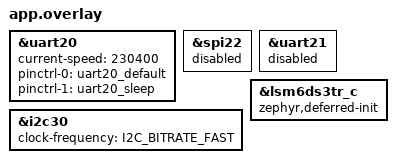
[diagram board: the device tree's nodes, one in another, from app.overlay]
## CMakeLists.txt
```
# Copyright 2026 XR IMU contributors
# SPDX-License-Identifier: Apache-2.0
cmake_minimum_required(VERSION 3.20.0)

find_package(Zephyr REQUIRED HINTS $ENV{ZEPHYR_BASE})
project(xr_imu_xiao_nrf54l15_sense)

target_sources(app PRIVATE
    src/main.c
    src/xr_controller_v1.c
)

target_include_directories(app PRIVATE include)
```

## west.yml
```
manifest:
  version: "1.2"

  remotes:
    - name: zephyrproject-rtos
      url-base: https://github.com/zephyrproject-rtos

  projects:
    - name: zephyr
      remote: zephyrproject-rtos
      revision: v4.4.0
      import:
        name-allowlist:
          - cmsis
          - cmsis_6
          - hal_nordic

  self:
    path: xr-imu-xiao-nrf54l15-sense
```

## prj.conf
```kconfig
# Binary-only UART transport. Never enable console/log output on uart20.
CONFIG_SERIAL=y
CONFIG_UART_ASYNC_API=y
CONFIG_UART_ASYNC_TX_CACHE_SIZE=64
CONFIG_CONSOLE=n
CONFIG_UART_CONSOLE=n
CONFIG_STDOUT_CONSOLE=n
CONFIG_PRINTK=n
CONFIG_LOG=n
CONFIG_BOOT_BANNER=n

# The Sense IMU rail is controlled by the board fixed regulator pdm_imu_pwr
# on P0.1. It must be enabled before the LSM6DSL driver initializes.
CONFIG_GPIO=y
CONFIG_REGULATOR=y
CONFIG_REGULATOR_FIXED=y
CONFIG_I2C=y
CONFIG_SENSOR=y
CONFIG_LSM6DSL=y
CONFIG_FPU=y

CONFIG_MAIN_STACK_SIZE=2048
CONFIG_SYSTEM_WORKQUEUE_STACK_SIZE=1024
CONFIG_HEAP_MEM_POOL_SIZE=0
CONFIG_TICKLESS_KERNEL=y

# Fixed sensor configuration. Avoid runtime sensor_attr_set() during startup.
# Kconfig ODR value 5 = 208 Hz for both accelerometer and gyroscope.
CONFIG_LSM6DSL_ACCEL_FS=16
CONFIG_LSM6DSL_ACCEL_ODR=5
CONFIG_LSM6DSL_GYRO_FS=2000
CONFIG_LSM6DSL_GYRO_ODR=5

CONFIG_HWINFO=y
```

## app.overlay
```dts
/*
 * Copyright 2026 XR IMU contributors
 * SPDX-License-Identifier: Apache-2.0
 */

#include <zephyr/dt-bindings/i2c/i2c.h>

/* uart20 is connected to the on-board SAMD11 CMSIS-DAP/CDC bridge. */
&uart20 {
    current-speed = <230400>;
    pinctrl-0 = <&uart20_default>;
    pinctrl-1 = <&uart20_sleep>;
    pinctrl-names = "default", "sleep";
    status = "okay";
};

/*
 * The upstream board DTS enables spi22 even though its SCK/MISO pins overlap
 * uart20 RX/TX (P1.8/P1.9). Disable it or its pinctrl can steal the UART pins
 * connected to the on-board SAMD11 CDC bridge.
 */
&spi22 {
    status = "disabled";
};

/* P2.7 is also used by the SWO/debug domain; this application does not need
 * the second UART, so keep it disabled while CMSIS-DAP is attached.
 */
&uart21 {
    status = "disabled";
};

/* Keep the two 6-byte sensor register reads comfortably below 2.4 ms. */
&i2c30 {
    clock-frequency = <I2C_BITRATE_FAST>;
};

&lsm6ds3tr_c {
    status = "okay";

    /* Power is controlled by P0.1. Initialize only after main() has
     * explicitly enabled the rail and verified the I2C identity.
     */
    zephyr,deferred-init;
};
```

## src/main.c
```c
/*
 * Copyright 2026 XR IMU contributors
 * SPDX-License-Identifier: Apache-2.0
 */
#include <zephyr/device.h>
#include <zephyr/devicetree.h>
#include <zephyr/drivers/gpio.h>
#include <zephyr/drivers/hwinfo.h>
#include <zephyr/drivers/i2c.h>
#include <zephyr/drivers/sensor.h>
#include <zephyr/drivers/uart.h>
#include <zephyr/kernel.h>
#include <zephyr/sys/util.h>

#include <errno.h>
#include <stdint.h>
#include <stddef.h>

#include "xr_controller_v1.h"

#define XR_IMU_SAMPLE_RATE_HZ 208U
#define XR_IMU_SAMPLE_PERIOD_US_CEIL \
    ((1000000U + XR_IMU_SAMPLE_RATE_HZ - 1U) / XR_IMU_SAMPLE_RATE_HZ)
#define XR_IMU_TX_QUEUE_DEPTH 128U
#define XR_IMU_TX_STACK_SIZE 1536U
#define XR_IMU_TX_PRIORITY 2
#define XR_CONTROLLER_IDENTITY_PERIOD_SAMPLES XR_IMU_SAMPLE_RATE_HZ
#define XR_IMU_TX_MAX_PACKET_SIZE XR_CONTROLLER_V1_PACKET_SIZE

struct tx_packet {
    uint16_t size;
    uint8_t bytes[XR_IMU_TX_MAX_PACKET_SIZE];
};

K_MSGQ_DEFINE(tx_queue, sizeof(struct tx_packet), XR_IMU_TX_QUEUE_DEPTH, 4);

#define XR_IMU_NODE DT_ALIAS(imu0)
static const struct device *const imu_dev = DEVICE_DT_GET(XR_IMU_NODE);
static const struct i2c_dt_spec imu_i2c = I2C_DT_SPEC_GET(XR_IMU_NODE);
static const struct gpio_dt_spec imu_power =
    GPIO_DT_SPEC_GET(DT_NODELABEL(pdm_imu_pwr), enable_gpios);
#define XR_IMU_UART_NODE DT_NODELABEL(uart20)
#define XR_IMU_UART_BAUD DT_PROP(XR_IMU_UART_NODE, current_speed)
#define XR_IMU_UART_BITS_PER_BYTE 10U
#define XR_IMU_UART_MAX_LOAD_PERCENT 90U

BUILD_ASSERT(
    ((XR_IMU_SAMPLE_RATE_HZ * XR_CONTROLLER_V1_PACKET_SIZE) +
      XR_CONTROLLER_IDENTITY_V1_PACKET_SIZE) *
        XR_IMU_UART_BITS_PER_BYTE * 100U <=
        XR_IMU_UART_BAUD * XR_IMU_UART_MAX_LOAD_PERCENT,
    "xr_controller_v1 stream exceeds the configured UART throughput budget");

static const struct device *const uart_dev = DEVICE_DT_GET(XR_IMU_UART_NODE);

#if DT_HAS_ALIAS(led0)
static const struct gpio_dt_spec status_led = GPIO_DT_SPEC_GET(DT_ALIAS(led0), gpios);
#endif

static uint64_t monotonic_time_us(void)
{
    return k_cyc_to_us_floor64(k_cycle_get_64());
}

K_MUTEX_DEFINE(uart_tx_mutex);
K_SEM_DEFINE(uart_tx_done, 0, 1);

static int uart_tx_result;

static void uart_event_callback(const struct device *dev,
                                struct uart_event *event,
                                void *user_data)
{
    ARG_UNUSED(dev);
    ARG_UNUSED(user_data);

    switch (event->type) {
    case UART_TX_DONE:
        uart_tx_result = 0;
        k_sem_give(&uart_tx_done);
        break;
    case UART_TX_ABORTED:
        uart_tx_result = -EIO;
        k_sem_give(&uart_tx_done);
        break;
    default:
        break;
    }
}

static int uart_write_raw(const uint8_t *data, size_t size)
{
    int rc;

    if (!device_is_ready(uart_dev)) {
        return -ENODEV;
    }
    if (size == 0U) {
        return 0;
    }

    k_mutex_lock(&uart_tx_mutex, K_FOREVER);
    k_sem_reset(&uart_tx_done);
    uart_tx_result = -EINPROGRESS;

    rc = uart_tx(uart_dev, data, size, SYS_FOREVER_US);
    if (rc == 0) {
        rc = k_sem_take(&uart_tx_done, K_MSEC(1000));
        if (rc == 0) {
            rc = uart_tx_result;
        } else {
            (void)uart_tx_abort(uart_dev);
            rc = -ETIMEDOUT;
        }
    }

    k_mutex_unlock(&uart_tx_mutex);
    return rc;
}

static void uart_write_text(const char *text)
{
    size_t size = 0U;

    while (text[size] != '\0') {
        ++size;
    }
    (void)uart_write_raw((const uint8_t *)text, size);
}

static char hex_digit(uint8_t value)
{
    value &= 0x0fU;
    return value < 10U ? (char)('0' + value) : (char)('A' + value - 10U);
}

static void uart_write_status_hex8(const char *prefix, uint8_t value)
{
    char suffix[4] = {hex_digit(value >> 4), hex_digit(value), '\n', '\0'};
    uart_write_text(prefix);
    uart_write_text(suffix);
}

static void uart_write_status_i32(const char *prefix, int32_t value)
{
    char digits[12];
    char out[14];
    size_t count = 0U;
    size_t pos = 0U;
    uint32_t magnitude;

    if (value < 0) {
        out[pos++] = '-';
        magnitude = (uint32_t)(-(int64_t)value);
    } else {
        magnitude = (uint32_t)value;
    }

    do {
        digits[count++] = (char)('0' + (magnitude % 10U));
        magnitude /= 10U;
    } while (magnitude != 0U);

    while (count != 0U) {
        out[pos++] = digits[--count];
    }
    out[pos++] = '\n';
    out[pos] = '\0';

    uart_write_text(prefix);
    uart_write_text(out);
}

static int probe_who_am_i(uint16_t address, uint8_t *value)
{
    return i2c_reg_read_byte(imu_i2c.bus, address, 0x0fU, value);
}

static void fatal_signal(const char *status)
{
#if DT_HAS_ALIAS(led0)
    const bool led_ready = gpio_is_ready_dt(&status_led) &&
        gpio_pin_configure_dt(&status_led, GPIO_OUTPUT_INACTIVE) == 0;
#else
    const bool led_ready = false;
#endif

    while (true) {
        uart_write_text(status);
#if DT_HAS_ALIAS(led0)
        if (led_ready) {
            for (int i = 0; i < 6; ++i) {
                (void)gpio_pin_toggle_dt(&status_led);
                k_sleep(K_MSEC(100));
            }
        }
#endif
        k_sleep(K_MSEC(400));
    }
}

static void tx_thread(void *arg1, void *arg2, void *arg3)
{
    ARG_UNUSED(arg1);
    ARG_UNUSED(arg2);
    ARG_UNUSED(arg3);

    struct tx_packet packet;

    while (true) {
        (void)k_msgq_get(&tx_queue, &packet, K_FOREVER);
        if (uart_write_raw(packet.bytes, packet.size) < 0) {
            k_sleep(K_MSEC(10));
        }
    }
}

K_THREAD_DEFINE(tx_thread_id, XR_IMU_TX_STACK_SIZE, tx_thread,
                NULL, NULL, NULL, XR_IMU_TX_PRIORITY, 0, 0);

int main(void)
{
    struct sensor_value gyro[3];
    struct sensor_value accel[3];
    struct tx_packet packet = {
        .size = XR_CONTROLLER_V1_PACKET_SIZE,
    };
    struct tx_packet identity_packet = {
        .size = XR_CONTROLLER_IDENTITY_V1_PACKET_SIZE,
    };
    xr_controller_identity_v1_t identity = {0};
    uint32_t sequence = 0U;
    uint64_t schedule_origin_us;
    uint64_t sample_index = 0U;
    uint32_t consecutive_fetch_errors = 0U;
    bool streaming_announced = false;

    if (!device_is_ready(uart_dev)) {
        fatal_signal("XRIMU_STATUS:UART_NOT_READY\n");
    }

    const int callback_rc = uart_callback_set(uart_dev, uart_event_callback, NULL);
    if (callback_rc < 0) {
        fatal_signal("XRIMU_STATUS:UART_ASYNC_INIT_FAILED\n");
    }

    uart_write_text("XRIMU_STATUS:BOOT\n");

    const ssize_t device_uid_size = hwinfo_get_device_id(
        identity.device_uid, sizeof(identity.device_uid));
    if (device_uid_size > 0) {
        identity.device_uid_size = (uint8_t)MIN(
            (size_t)device_uid_size, sizeof(identity.device_uid));
        identity.flags = XR_CONTROLLER_IDENTITY_V1_FLAG_DEVICE_UID_VALID;
        uart_write_text("XRIMU_STATUS:DEVICE_UID_READY\n");
    } else {
        identity.device_uid_size = 0U;
        identity.flags = 0U;
        uart_write_text("XRIMU_STATUS:DEVICE_UID_UNAVAILABLE\n");
    }
    xr_controller_identity_v1_encode(identity_packet.bytes, &identity);
    (void)k_msgq_put(&tx_queue, &identity_packet, K_NO_WAIT);

    if (!device_is_ready(imu_i2c.bus)) {
        fatal_signal("XRIMU_STATUS:I2C30_NOT_READY\n");
    }

    if (!gpio_is_ready_dt(&imu_power)) {
        fatal_signal("XRIMU_STATUS:IMU_POWER_GPIO_NOT_READY\n");
    }

    const int power_rc = gpio_pin_configure_dt(&imu_power, GPIO_OUTPUT_ACTIVE);
    if (power_rc < 0) {
        uart_write_status_i32("XRIMU_STATUS:IMU_POWER_RC=", power_rc);
        fatal_signal("XRIMU_STATUS:IMU_POWER_FAILED\n");
    }

    /* The datasheet turn-on delay is short, but leave generous margin before
     * probing and initializing the sensor driver.
     */
    k_sleep(K_MSEC(50));

    uint8_t who_6a = 0U;
    uint8_t who_6b = 0U;
    const int probe_6a_rc = probe_who_am_i(0x6aU, &who_6a);
    const int probe_6b_rc = probe_who_am_i(0x6bU, &who_6b);

    if (probe_6a_rc == 0) {
        uart_write_status_hex8("XRIMU_STATUS:WHOAMI_6A=0x", who_6a);
    } else {
        uart_write_status_i32("XRIMU_STATUS:WHOAMI_6A_RC=", probe_6a_rc);
    }

    if (probe_6b_rc == 0) {
        uart_write_status_hex8("XRIMU_STATUS:WHOAMI_6B=0x", who_6b);
    } else {
        uart_write_status_i32("XRIMU_STATUS:WHOAMI_6B_RC=", probe_6b_rc);
    }

    if (probe_6a_rc != 0 || who_6a != 0x6aU) {
        if (probe_6b_rc == 0 && who_6b == 0x6aU) {
            fatal_signal("XRIMU_STATUS:IMU_FOUND_AT_0X6B\n");
        }
        fatal_signal("XRIMU_STATUS:IMU_NOT_FOUND\n");
    }

    const int init_rc = device_init(imu_dev);
    if (init_rc < 0 && init_rc != -EALREADY) {
        uart_write_status_i32("XRIMU_STATUS:IMU_INIT_RC=", init_rc);
        fatal_signal("XRIMU_STATUS:IMU_INIT_FAILED\n");
    }

    if (!device_is_ready(imu_dev)) {
        uart_write_status_i32("XRIMU_STATUS:IMU_INIT_RC=", init_rc);
        fatal_signal("XRIMU_STATUS:IMU_NOT_READY_AFTER_INIT\n");
    }

    uart_write_text("XRIMU_STATUS:IMU_READY\n");

    /* The fixed Kconfig ODR/full-scale settings are applied by the driver. */
    k_sleep(K_MSEC(20));
    schedule_origin_us = monotonic_time_us();

    while (true) {
        xr_controller_v1_sample_t sample = {
            .flags = XR_CONTROLLER_V1_FLAG_TIMESTAMP_VALID,
        };
        const uint64_t fetch_start_us = monotonic_time_us();
        const int fetch_rc = sensor_sample_fetch(imu_dev);
        const uint64_t fetch_end_us = monotonic_time_us();

        const int gyro_rc = fetch_rc == 0 ?
            sensor_channel_get(imu_dev, SENSOR_CHAN_GYRO_XYZ, gyro) : fetch_rc;
        const int accel_rc = (fetch_rc == 0 && gyro_rc == 0) ?
            sensor_channel_get(imu_dev, SENSOR_CHAN_ACCEL_XYZ, accel) : gyro_rc;

        if (fetch_rc == 0 && gyro_rc == 0 && accel_rc == 0) {
            consecutive_fetch_errors = 0U;
            if (!streaming_announced) {
                uart_write_text("XRIMU_STATUS:STREAMING\n");
                streaming_announced = true;
            }

            sample.sequence = sequence++;
            /* Midpoint of the I2C register read is a better acquisition estimate
             * than the later packet-transmit time.
             */
            sample.timestamp_us = fetch_start_us + ((fetch_end_us - fetch_start_us) / 2U);

            for (size_t axis = 0U; axis < 3U; ++axis) {
                sample.gyro_rad_s[axis] = sensor_value_to_float(&gyro[axis]);
                sample.accel_m_s2[axis] = sensor_value_to_float(&accel[axis]);
            }

            xr_controller_v1_encode(packet.bytes, &sample);

            /* Never block acquisition on serial output. A full queue drops this
             * sample; the monotonic sequence exposes the loss to the host.
             */
            (void)k_msgq_put(&tx_queue, &packet, K_NO_WAIT);

            /* Repeat identity once per second so hosts attaching after boot can
             * learn the hardware UID. This adds a separate 32-byte frame and
             * never replaces, delays, or changes the 208 Hz IMU schedule. */
            if ((sample.sequence % XR_CONTROLLER_IDENTITY_PERIOD_SAMPLES) == 0U) {
                (void)k_msgq_put(&tx_queue, &identity_packet, K_NO_WAIT);
            }
        } else {
            ++consecutive_fetch_errors;
            if (consecutive_fetch_errors == XR_IMU_SAMPLE_RATE_HZ) {
                uart_write_text("XRIMU_STATUS:IMU_READ_FAILED\n");
                consecutive_fetch_errors = 0U;
            }
        }

        /* Derive every deadline from the common origin. This distributes the
         * fractional 208 Hz period between 4807 and 4808 us without cumulative
         * integer-division drift.
         */
        ++sample_index;
        uint64_t next_sample_us = schedule_origin_us +
            ((sample_index * 1000000ULL) / XR_IMU_SAMPLE_RATE_HZ);
        const uint64_t now_us = monotonic_time_us();

        if (next_sample_us > now_us) {
            k_sleep(K_USEC(next_sample_us - now_us));
        } else if ((now_us - next_sample_us) >
                   (4U * XR_IMU_SAMPLE_PERIOD_US_CEIL)) {
            /* Do not repeatedly run late after a debugger stop or long stall. */
            schedule_origin_us = now_us;
            sample_index = 0U;
        }
    }

    return 0;
}
```

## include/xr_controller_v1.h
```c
/*
 * Copyright 2026 XR IMU contributors
 * SPDX-License-Identifier: Apache-2.0
 */
#ifndef XR_CONTROLLER_V1_H_
#define XR_CONTROLLER_V1_H_

#include <stddef.h>
#include <stdint.h>

#ifdef __cplusplus
extern "C" {
#endif

#define XR_CONTROLLER_V1_MAGIC_0 ((uint8_t)'X')
#define XR_CONTROLLER_V1_MAGIC_1 ((uint8_t)'C')
#define XR_CONTROLLER_V1_MAGIC_2 ((uint8_t)'T')
#define XR_CONTROLLER_V1_MAGIC_3 ((uint8_t)'L')
#define XR_CONTROLLER_V1_VERSION 1U

#define XR_CONTROLLER_V1_FLAG_TIMESTAMP_VALID 0x01U
#define XR_CONTROLLER_V1_FLAG_CONTROLS_VALID  0x02U
#define XR_CONTROLLER_V1_FLAG_BATTERY_VALID   0x04U

#define XR_CONTROLLER_V1_PACKET_SIZE 64U
#define XR_CONTROLLER_V1_CRC_OFFSET 60U
#define XR_CONTROLLER_V1_AXIS_COUNT 4U

/* Periodic identity frame interleaved with XCTL packets. It does not replace
 * or resize the 64-byte IMU packet, so the IMU sampling rate remains 208 Hz. */
#define XR_CONTROLLER_IDENTITY_V1_MAGIC_0 ((uint8_t)'X')
#define XR_CONTROLLER_IDENTITY_V1_MAGIC_1 ((uint8_t)'C')
#define XR_CONTROLLER_IDENTITY_V1_MAGIC_2 ((uint8_t)'I')
#define XR_CONTROLLER_IDENTITY_V1_MAGIC_3 ((uint8_t)'D')
#define XR_CONTROLLER_IDENTITY_V1_VERSION 1U
#define XR_CONTROLLER_IDENTITY_V1_FLAG_DEVICE_UID_VALID 0x01U
#define XR_CONTROLLER_IDENTITY_V1_PACKET_SIZE 32U
#define XR_CONTROLLER_IDENTITY_V1_CRC_OFFSET 28U
#define XR_CONTROLLER_DEVICE_UID_MAX_SIZE 16U

enum xr_controller_v1_button_bits {
    XR_CONTROLLER_V1_BUTTON_A           = UINT32_C(1) << 0,
    XR_CONTROLLER_V1_BUTTON_B           = UINT32_C(1) << 1,
    XR_CONTROLLER_V1_BUTTON_C           = UINT32_C(1) << 2,
    XR_CONTROLLER_V1_BUTTON_TRIGGER     = UINT32_C(1) << 3,
    XR_CONTROLLER_V1_BUTTON_GRIP        = UINT32_C(1) << 4,
    XR_CONTROLLER_V1_BUTTON_MENU        = UINT32_C(1) << 5,
    XR_CONTROLLER_V1_BUTTON_STICK_CLICK = UINT32_C(1) << 6,
    XR_CONTROLLER_V1_BUTTON_DPAD_UP     = UINT32_C(1) << 7,
    XR_CONTROLLER_V1_BUTTON_DPAD_DOWN   = UINT32_C(1) << 8,
    XR_CONTROLLER_V1_BUTTON_DPAD_LEFT   = UINT32_C(1) << 9,
    XR_CONTROLLER_V1_BUTTON_DPAD_RIGHT  = UINT32_C(1) << 10,
};

enum xr_controller_v1_axis_index {
    XR_CONTROLLER_V1_AXIS_THUMBSTICK_X = 0,
    XR_CONTROLLER_V1_AXIS_THUMBSTICK_Y = 1,
    XR_CONTROLLER_V1_AXIS_TRIGGER = 2,
    XR_CONTROLLER_V1_AXIS_GRIP = 3,
};

typedef struct xr_controller_identity_v1 {
    uint8_t flags;
    uint8_t device_uid_size;
    uint8_t device_uid[XR_CONTROLLER_DEVICE_UID_MAX_SIZE];
} xr_controller_identity_v1_t;

typedef struct xr_controller_v1_sample {
    uint32_t sequence;
    uint64_t timestamp_us;
    float gyro_rad_s[3];
    float accel_m_s2[3];
    uint32_t buttons;
    int16_t axes[XR_CONTROLLER_V1_AXIS_COUNT];
    uint16_t battery_mv;
    uint16_t controller_status;
    uint8_t flags;
} xr_controller_v1_sample_t;

uint32_t xr_controller_crc32_ieee(const uint8_t *data, size_t size);

void xr_controller_identity_v1_encode(
    uint8_t packet[XR_CONTROLLER_IDENTITY_V1_PACKET_SIZE],
    const xr_controller_identity_v1_t *identity);

void xr_controller_v1_encode(
    uint8_t packet[XR_CONTROLLER_V1_PACKET_SIZE],
    const xr_controller_v1_sample_t *sample);

#ifdef __cplusplus
}
#endif

#endif /* XR_CONTROLLER_V1_H_ */
```

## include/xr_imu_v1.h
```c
/*
 * Copyright 2026 XR IMU contributors
 * SPDX-License-Identifier: Apache-2.0
 */
#ifndef XR_IMU_V1_H_
#define XR_IMU_V1_H_

#include <stddef.h>
#include <stdint.h>

#ifdef __cplusplus
extern "C" {
#endif

#define XR_IMU_V1_MAGIC_0 ((uint8_t)'X')
#define XR_IMU_V1_MAGIC_1 ((uint8_t)'I')
#define XR_IMU_V1_MAGIC_2 ((uint8_t)'M')
#define XR_IMU_V1_MAGIC_3 ((uint8_t)'U')
#define XR_IMU_V1_VERSION 1U
#define XR_IMU_V1_FLAG_TIMESTAMP_VALID 0x01U
#define XR_IMU_V1_PACKET_SIZE 48U
#define XR_IMU_V1_CRC_OFFSET 44U

typedef struct xr_imu_v1_sample {
    uint32_t sequence;
    uint64_t timestamp_us;
    float gyro_rad_s[3];
    float accel_m_s2[3];
    uint8_t flags;
} xr_imu_v1_sample_t;

uint32_t xr_imu_crc32_ieee(const uint8_t *data, size_t size);

void xr_imu_v1_encode(uint8_t packet[XR_IMU_V1_PACKET_SIZE],
                      const xr_imu_v1_sample_t *sample);

#ifdef __cplusplus
}
#endif

#endif /* XR_IMU_V1_H_ */
```

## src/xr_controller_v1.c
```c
/*
 * Copyright 2026 XR IMU contributors
 * SPDX-License-Identifier: Apache-2.0
 */
#include "xr_controller_v1.h"

#include <string.h>

_Static_assert(sizeof(float) == 4U,
               "xr_controller_v1 requires IEEE-754 binary32 float");

static void put_u16_le(uint8_t *dst, uint16_t value)
{
    dst[0] = (uint8_t)(value & 0xffU);
    dst[1] = (uint8_t)((value >> 8U) & 0xffU);
}

static void put_i16_le(uint8_t *dst, int16_t value)
{
    put_u16_le(dst, (uint16_t)value);
}

static void put_u32_le(uint8_t *dst, uint32_t value)
{
    dst[0] = (uint8_t)(value & 0xffU);
    dst[1] = (uint8_t)((value >> 8U) & 0xffU);
    dst[2] = (uint8_t)((value >> 16U) & 0xffU);
    dst[3] = (uint8_t)((value >> 24U) & 0xffU);
}

static void put_u64_le(uint8_t *dst, uint64_t value)
{
    for (size_t i = 0U; i < 8U; ++i) {
        dst[i] = (uint8_t)((value >> (8U * i)) & 0xffU);
    }
}

static void put_f32_le(uint8_t *dst, float value)
{
    uint32_t bits = 0U;
    memcpy(&bits, &value, sizeof(bits));
    put_u32_le(dst, bits);
}

uint32_t xr_controller_crc32_ieee(const uint8_t *data, size_t size)
{
    uint32_t crc = 0xffffffffU;

    for (size_t i = 0U; i < size; ++i) {
        crc ^= data[i];
        for (uint32_t bit = 0U; bit < 8U; ++bit) {
            const uint32_t mask = (uint32_t)-(int32_t)(crc & 1U);
            crc = (crc >> 1U) ^ (0xedb88320U & mask);
        }
    }

    return crc ^ 0xffffffffU;
}

void xr_controller_identity_v1_encode(
    uint8_t packet[XR_CONTROLLER_IDENTITY_V1_PACKET_SIZE],
    const xr_controller_identity_v1_t *identity)
{
    uint8_t uid_size = identity->device_uid_size;
    if (uid_size > XR_CONTROLLER_DEVICE_UID_MAX_SIZE) {
        uid_size = XR_CONTROLLER_DEVICE_UID_MAX_SIZE;
    }

    memset(packet, 0, XR_CONTROLLER_IDENTITY_V1_PACKET_SIZE);
    packet[0] = XR_CONTROLLER_IDENTITY_V1_MAGIC_0;
    packet[1] = XR_CONTROLLER_IDENTITY_V1_MAGIC_1;
    packet[2] = XR_CONTROLLER_IDENTITY_V1_MAGIC_2;
    packet[3] = XR_CONTROLLER_IDENTITY_V1_MAGIC_3;
    packet[4] = XR_CONTROLLER_IDENTITY_V1_VERSION;
    packet[5] = identity->flags;
    put_u16_le(&packet[6], XR_CONTROLLER_IDENTITY_V1_PACKET_SIZE);
    packet[8] = uid_size;
    packet[9] = XR_CONTROLLER_V1_VERSION;
    memcpy(&packet[12], identity->device_uid, uid_size);
    put_u32_le(&packet[XR_CONTROLLER_IDENTITY_V1_CRC_OFFSET],
               xr_controller_crc32_ieee(
                   packet, XR_CONTROLLER_IDENTITY_V1_CRC_OFFSET));
}

void xr_controller_v1_encode(
    uint8_t packet[XR_CONTROLLER_V1_PACKET_SIZE],
    const xr_controller_v1_sample_t *sample)
{
    memset(packet, 0, XR_CONTROLLER_V1_PACKET_SIZE);

    packet[0] = XR_CONTROLLER_V1_MAGIC_0;
    packet[1] = XR_CONTROLLER_V1_MAGIC_1;
    packet[2] = XR_CONTROLLER_V1_MAGIC_2;
    packet[3] = XR_CONTROLLER_V1_MAGIC_3;
    packet[4] = XR_CONTROLLER_V1_VERSION;
    packet[5] = sample->flags;
    put_u16_le(&packet[6], XR_CONTROLLER_V1_PACKET_SIZE);
    put_u32_le(&packet[8], sample->sequence);
    put_u64_le(&packet[12], sample->timestamp_us);

    for (size_t i = 0U; i < 3U; ++i) {
        put_f32_le(&packet[20U + (i * 4U)], sample->gyro_rad_s[i]);
        put_f32_le(&packet[32U + (i * 4U)], sample->accel_m_s2[i]);
    }

    put_u32_le(&packet[44], sample->buttons);
    for (size_t i = 0U; i < XR_CONTROLLER_V1_AXIS_COUNT; ++i) {
        put_i16_le(&packet[48U + (i * 2U)], sample->axes[i]);
    }
    put_u16_le(&packet[56], sample->battery_mv);
    put_u16_le(&packet[58], sample->controller_status);

    put_u32_le(&packet[XR_CONTROLLER_V1_CRC_OFFSET],
               xr_controller_crc32_ieee(packet,
                                         XR_CONTROLLER_V1_CRC_OFFSET));
}
```

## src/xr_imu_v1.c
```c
/*
 * Copyright 2026 XR IMU contributors
 * SPDX-License-Identifier: Apache-2.0
 */
#include "xr_imu_v1.h"

#include <string.h>

_Static_assert(sizeof(float) == 4U, "xr_imu_v1 requires IEEE-754 binary32 float");

static void put_u16_le(uint8_t *dst, uint16_t value)
{
    dst[0] = (uint8_t)(value & 0xffU);
    dst[1] = (uint8_t)((value >> 8U) & 0xffU);
}

static void put_u32_le(uint8_t *dst, uint32_t value)
{
    dst[0] = (uint8_t)(value & 0xffU);
    dst[1] = (uint8_t)((value >> 8U) & 0xffU);
    dst[2] = (uint8_t)((value >> 16U) & 0xffU);
    dst[3] = (uint8_t)((value >> 24U) & 0xffU);
}

static void put_u64_le(uint8_t *dst, uint64_t value)
{
    for (size_t i = 0U; i < 8U; ++i) {
        dst[i] = (uint8_t)((value >> (8U * i)) & 0xffU);
    }
}

static void put_f32_le(uint8_t *dst, float value)
{
    uint32_t bits = 0U;
    memcpy(&bits, &value, sizeof(bits));
    put_u32_le(dst, bits);
}

uint32_t xr_imu_crc32_ieee(const uint8_t *data, size_t size)
{
    uint32_t crc = 0xffffffffU;

    for (size_t i = 0U; i < size; ++i) {
        crc ^= data[i];
        for (uint32_t bit = 0U; bit < 8U; ++bit) {
            const uint32_t mask = (uint32_t)-(int32_t)(crc & 1U);
            crc = (crc >> 1U) ^ (0xedb88320U & mask);
        }
    }

    return crc ^ 0xffffffffU;
}

void xr_imu_v1_encode(uint8_t packet[XR_IMU_V1_PACKET_SIZE],
                      const xr_imu_v1_sample_t *sample)
{
    memset(packet, 0, XR_IMU_V1_PACKET_SIZE);

    packet[0] = XR_IMU_V1_MAGIC_0;
    packet[1] = XR_IMU_V1_MAGIC_1;
    packet[2] = XR_IMU_V1_MAGIC_2;
    packet[3] = XR_IMU_V1_MAGIC_3;
    packet[4] = XR_IMU_V1_VERSION;
    packet[5] = sample->flags;
    put_u16_le(&packet[6], XR_IMU_V1_PACKET_SIZE);
    put_u32_le(&packet[8], sample->sequence);
    put_u64_le(&packet[12], sample->timestamp_us);

    for (size_t i = 0U; i < 3U; ++i) {
        put_f32_le(&packet[20U + (i * 4U)], sample->gyro_rad_s[i]);
        put_f32_le(&packet[32U + (i * 4U)], sample->accel_m_s2[i]);
    }

    put_u32_le(&packet[XR_IMU_V1_CRC_OFFSET],
               xr_imu_crc32_ieee(packet, XR_IMU_V1_CRC_OFFSET));
}
```
